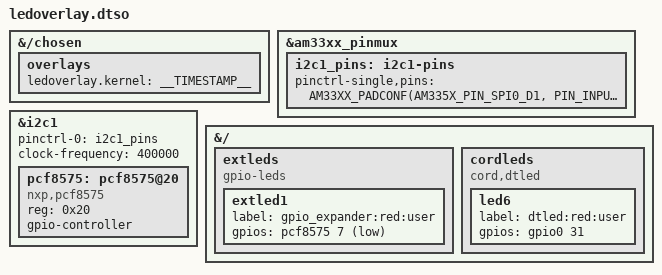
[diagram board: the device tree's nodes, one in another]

/dts-v1/;
/plugin/; // tell dtc that this is an overlay


#include <dt-bindings/gpio/gpio.h>
#include <dt-bindings/pinctrl/am33xx.h>

/*
 * Helper to show loaded overlays under: /proc/device-tree/chosen/overlays/
 */
&{/chosen} {
        overlays {
            ledoverlay.kernel = __TIMESTAMP__;
        };
};

&{am33xx_pinmux} {

    i2c1_pins: i2c1-pins {
        pinctrl-single,pins = <
            AM33XX_PADCONF(AM335X_PIN_SPI0_D1, PIN_INPUT_PULLUP, MUX_MODE2)     /* spi0_d1.i2c1_sda */
            AM33XX_PADCONF(AM335X_PIN_SPI0_CS0, PIN_INPUT_PULLUP, MUX_MODE2)    /* spi0_cs0.i2c1_scl */
        >;
    };
};

&{i2c1} {

    pinctrl-names = "default";
    pinctrl-0 = <&i2c1_pins>;

    status = "okay";
    clock-frequency = <400000>;

    // It's a good convention to put the i2c address here in the node name
    pcf8575: pcf8575@20 {
        compatible = "nxp,pcf8575";
        // 0x20 is the i2c chip's address
        reg = <0x20>;
        // This means this node is a gpio provider
        gpio-controller;
        #gpio-cells = <2>;
    };
};

// Doing "&{/}" is the more modern way of doing:
// fragment@0 {
//         target-path = "/";
//         __overlay__ {
//             cordleds {
//                 ...
//             };
//         };
// };
// The old way would also work but the modern way is cleaner as it fills in the fragment
// and __overlay__ keyword. Because it fills the fragment@0 automatically, the old way might
// have an advantage here because other fragments can be added manually. I don't know if the
// modern way has a way to do that.
// Anyways modern way is cleaner but I don't know what upstream kernel prefers.
// The docs only mention the legacy way:
// https://www.kernel.org/doc/Documentation/devicetree/overlay-notes.txt
&{/} {

    extleds {
        compatible = "gpio-leds";

        extled1 {
            label = "gpio_expander:red:user";
            // The gpio expander is a current sink so it's active low
            gpios = <&pcf8575 7 GPIO_ACTIVE_LOW>;
        };
    };

    // Create a new cordleds node
    cordleds {

        // Use the driver with the matching "compatible", in this case "cord,dtled"
        compatible = "cord,dtled";

        led6 {
            label = "dtled:red:user";
            gpios = <&gpio0 31 GPIO_ACTIVE_HIGH>;
        };

    };

};
